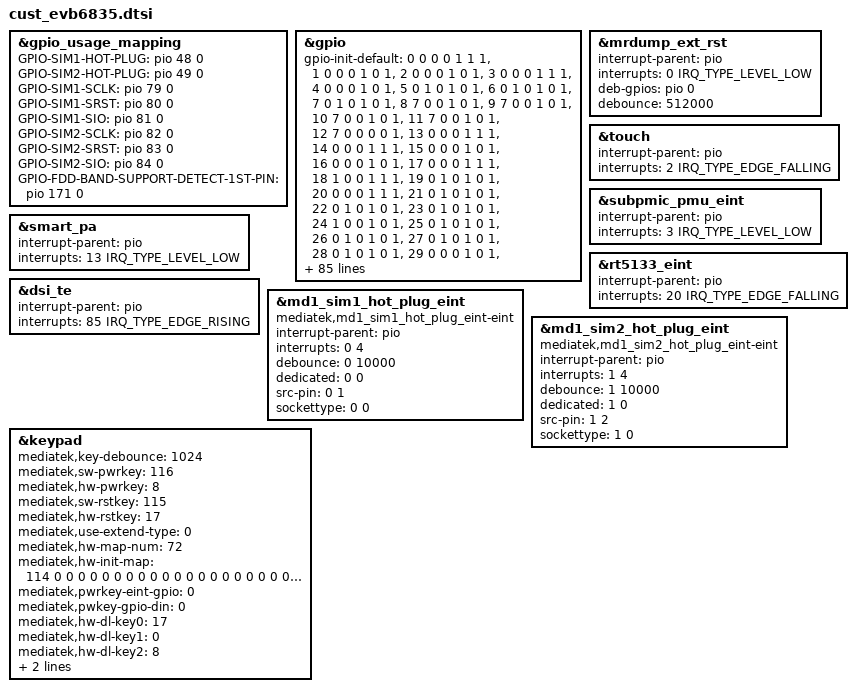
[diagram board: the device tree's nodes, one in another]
// SPDX-License-Identifier: (GPL-2.0-only OR BSD-2-Clause)
/*
 * Copyright (c) 2019 MediaTek Inc.
 */

/*
 * Generated by MTK SP DrvGen Version: 3.5.160809 for MT6835_6377.
 * 2022-09-23 20:14:52
 * Do Not Modify The File.
 * Copyright Mediatek Inc. (c) 2016.
 */

/*************************
 * ADC DTSI File
 ************************/



/*************************
 * CLK_BUF DTSI File
 ************************/



/*************************
 * I2C DTSI File
 ************************/



/*************************
 * GPIO DTSI File
 ************************/

&gpio_usage_mapping {
	GPIO-SIM1-HOT-PLUG = <&pio 48 0>;
	GPIO-SIM2-HOT-PLUG = <&pio 49 0>;
	GPIO-SIM1-SCLK = <&pio 79 0>;
	GPIO-SIM1-SRST = <&pio 80 0>;
	GPIO-SIM1-SIO = <&pio 81 0>;
	GPIO-SIM2-SCLK = <&pio 82 0>;
	GPIO-SIM2-SRST = <&pio 83 0>;
	GPIO-SIM2-SIO = <&pio 84 0>;
	GPIO-FDD-BAND-SUPPORT-DETECT-1ST-PIN = <&pio 171 0>;
};

&gpio{
	gpio-init-default = <0 0 0 0 1 1 1>,
		<1 0 0 0 1 0 1>,
		<2 0 0 0 1 0 1>,
		<3 0 0 0 1 1 1>,
		<4 0 0 0 1 0 1>,
		<5 0 1 0 1 0 1>,
		<6 0 1 0 1 0 1>,
		<7 0 1 0 1 0 1>,
		<8 7 0 0 1 0 1>,
		<9 7 0 0 1 0 1>,
		<10 7 0 0 1 0 1>,
		<11 7 0 0 1 0 1>,
		<12 7 0 0 0 0 1>,
		<13 0 0 0 1 1 1>,
		<14 0 0 0 1 1 1>,
		<15 0 0 0 1 0 1>,
		<16 0 0 0 1 0 1>,
		<17 0 0 0 1 1 1>,
		<18 1 0 0 1 1 1>,
		<19 0 1 0 1 0 1>,
		<20 0 0 0 1 1 1>,
		<21 0 1 0 1 0 1>,
		<22 0 1 0 1 0 1>,
		<23 0 1 0 1 0 1>,
		<24 1 0 0 1 0 1>,
		<25 0 1 0 1 0 1>,
		<26 0 1 0 1 0 1>,
		<27 0 1 0 1 0 1>,
		<28 0 1 0 1 0 1>,
		<29 0 0 0 1 0 1>,
		<30 0 1 0 1 0 1>,
		<31 1 0 0 1 1 1>,
		<32 7 0 0 1 1 1>,
		<33 7 0 0 1 0 1>,
		<34 3 0 0 1 0 1>,
		<35 3 0 0 1 1 1>,
		<36 1 0 0 1 0 1>,
		<37 1 0 0 1 0 1>,
		<38 1 0 0 1 0 1>,
		<39 1 0 0 1 0 1>,
		<40 1 0 0 1 0 1>,
		<41 1 0 0 1 0 1>,
		<42 1 0 0 1 0 1>,
		<43 0 1 0 1 0 1>,
		<44 1 0 0 0 0 1>,
		<45 1 0 0 1 0 1>,
		<46 1 0 0 0 0 1>,
		<47 3 0 0 1 0 1>,
		<48 1 0 0 1 1 1>,
		<49 1 0 0 1 1 1>,
		<50 1 0 0 0 0 1>,
		<51 1 0 0 1 1 1>,
		<52 1 0 0 0 0 1>,
		<53 1 0 0 1 1 1>,
		<54 0 1 0 1 0 1>,
		<55 7 0 0 1 0 1>,
		<56 7 0 0 1 0 1>,
		<57 7 0 0 1 0 1>,
		<58 7 0 0 0 0 1>,
		<59 7 0 0 1 0 1>,
		<60 2 0 0 1 0 1>,
		<61 2 0 0 1 1 1>,
		<62 2 0 0 1 0 1>,
		<63 2 0 0 1 0 1>,
		<64 1 0 0 1 0 1>,
		<65 1 0 0 1 1 1>,
		<66 1 0 0 1 0 1>,
		<67 1 0 0 1 0 1>,
		<68 1 0 0 1 0 1>,
		<69 1 0 0 1 1 1>,
		<70 1 0 0 1 0 1>,
		<71 1 0 0 1 0 1>,
		<73 1 0 0 0 0 1>,
		<74 1 0 0 1 1 1>,
		<75 1 0 0 1 1 1>,
		<76 1 0 0 1 1 1>,
		<77 1 0 0 1 1 1>,
		<78 1 0 0 1 1 1>,
		<79 1 0 0 0 0 1>,
		<80 1 0 0 0 0 1>,
		<81 1 0 0 1 1 1>,
		<82 1 0 0 0 0 1>,
		<83 1 0 0 0 0 1>,
		<84 1 0 0 1 1 1>,
		<85 1 0 0 1 0 1>,
		<86 1 0 0 0 0 1>,
		<87 1 0 0 0 0 1>,
		<88 1 0 0 1 0 1>,
		<89 1 0 0 1 0 1>,
		<90 1 0 0 1 0 1>,
		<91 1 0 0 1 0 1>,
		<92 0 0 0 1 0 1>,
		<93 1 0 0 1 0 1>,
		<94 1 0 0 1 0 1>,
		<95 1 0 0 0 0 1>,
		<96 1 0 0 0 0 1>,
		<97 1 0 0 0 0 1>,
		<98 1 0 0 0 0 1>,
		<99 1 0 0 0 0 1>,
		<100 1 0 0 0 0 1>,
		<101 1 0 0 0 0 1>,
		<102 1 0 0 0 0 1>,
		<103 1 0 0 0 0 1>,
		<104 1 0 0 0 0 1>,
		<105 1 0 0 0 0 1>,
		<106 1 0 0 0 0 1>,
		<107 1 0 0 0 0 1>,
		<108 1 0 0 0 0 1>,
		<109 1 0 0 0 0 1>,
		<110 1 0 0 0 0 1>,
		<111 1 0 0 0 0 1>,
		<112 1 0 0 0 0 1>,
		<113 1 0 0 0 0 1>,
		<114 1 0 0 0 0 1>,
		<115 1 0 0 0 0 0>,
		<116 1 0 0 1 0 0>,
		<117 1 0 0 0 0 0>,
		<118 1 0 0 1 0 0>,
		<119 1 0 0 0 0 0>,
		<120 1 0 0 1 0 0>,
		<121 1 0 0 0 0 0>,
		<122 1 0 0 1 0 0>,
		<123 4 0 0 1 0 1>,
		<124 4 0 0 1 0 1>,
		<125 1 0 0 1 0 1>,
		<126 1 0 0 1 0 1>,
		<127 0 0 0 1 0 1>,
		<128 0 0 0 1 0 1>,
		<129 2 0 0 1 1 1>,
		<130 2 0 0 1 1 1>,
		<131 1 0 0 1 1 1>,
		<132 1 0 0 1 1 1>,
		<133 0 1 1 1 0 1>,
		<134 0 1 0 1 0 1>,
		<135 1 0 0 1 1 1>,
		<136 1 0 0 1 1 1>,
		<137 1 0 0 1 1 1>,
		<138 1 0 0 1 1 1>,
		<139 1 0 0 1 1 1>,
		<140 1 0 0 1 1 1>,
		<141 0 1 0 1 0 1>,
		<142 0 1 0 1 0 1>,
		<143 1 0 0 1 1 1>,
		<144 1 0 0 1 1 1>,
		<145 3 0 0 1 1 1>,
		<146 3 0 0 1 1 1>,
		<147 0 1 0 1 0 1>,
		<148 0 1 0 1 0 1>,
		<149 4 0 0 1 0 1>,
		<150 0 1 0 1 0 1>,
		<151 0 0 0 1 0 1>,
		<152 1 0 0 0 0 1>,
		<153 1 0 0 0 0 1>,
		<154 1 0 0 0 0 1>,
		<155 1 0 0 0 0 1>,
		<156 1 0 0 0 0 1>,
		<157 1 0 0 0 0 1>,
		<158 1 0 0 0 0 1>,
		<159 1 0 0 1 0 1>,
		<160 1 0 0 0 0 1>,
		<161 1 0 0 0 0 1>,
		<162 1 0 0 0 0 1>,
		<163 1 0 0 0 0 1>,
		<164 1 0 0 0 0 1>,
		<165 0 0 0 1 0 1>,
		<166 1 0 0 0 0 1>,
		<167 1 0 0 0 0 1>,
		<168 1 0 0 1 0 1>,
		<169 1 0 0 1 0 1>,
		<170 0 1 0 1 0 1>,
		<171 0 0 0 0 0 1>,
		<172 0 0 0 1 0 1>,
		<173 0 0 0 1 0 1>,
		<174 0 0 0 1 0 1>,
		<175 0 0 0 1 0 1>,
		<176 0 0 0 1 0 1>,
		<177 0 0 0 1 0 1>,
		<178 0 0 0 1 0 1>,
		<179 0 0 0 1 0 1>,
		<180 0 0 0 1 0 1>,
		<193 0 0 0 1 0 0>,
		<194 0 0 0 1 0 0>,
		<195 0 0 0 1 0 0>,
		<196 0 0 0 1 0 0>,
		<197 0 0 0 1 0 0>,
		<198 0 0 0 1 0 0>,
		<199 0 0 0 1 0 0>,
		<200 0 0 0 1 0 0>,
		<201 0 0 0 1 0 0>,
		<202 0 0 0 1 0 0>,
		<203 0 0 0 1 0 0>,
		<204 0 0 0 1 0 0>,
		<205 0 0 0 1 0 0>,
		<206 0 0 0 1 0 0>,
		<207 0 0 0 1 0 0>,
		<208 0 0 0 1 0 0>,
		<209 0 0 0 1 0 0>,
		<210 0 0 0 1 0 0>,
		<211 0 0 0 1 0 0>,
		<212 0 0 0 1 0 0>;
};


/*************************
 * EINT DTSI File
 ************************/

#include <dt-bindings/interrupt-controller/irq.h>
#include <dt-bindings/interrupt-controller/arm-gic.h>

&mrdump_ext_rst {
	interrupt-parent = <&pio>;
	interrupts = <0 IRQ_TYPE_LEVEL_LOW>;
	deb-gpios = <&pio 0 0>;
	debounce = <512000>;
	status = "okay";
};

&touch {
	interrupt-parent = <&pio>;
	interrupts = <2 IRQ_TYPE_EDGE_FALLING>;
	status = "okay";
};

&subpmic_pmu_eint {
	interrupt-parent = <&pio>;
	interrupts = <3 IRQ_TYPE_LEVEL_LOW>;
	status = "okay";
};

&smart_pa {
	interrupt-parent = <&pio>;
	interrupts = <13 IRQ_TYPE_LEVEL_LOW>;
	status = "okay";
};

&rt5133_eint {
	interrupt-parent = <&pio>;
	interrupts = <20 IRQ_TYPE_EDGE_FALLING>;
	status = "okay";
};

&dsi_te {
	interrupt-parent = <&pio>;
	interrupts = <85 IRQ_TYPE_EDGE_RISING>;
	status = "okay";
};



/*************************
 * MD1_EINT DTSI File
 ************************/

&md1_sim1_hot_plug_eint {
	compatible = "mediatek,md1_sim1_hot_plug_eint-eint";
	interrupt-parent = <&pio>;
	interrupts = <0 4>;
	debounce = <0 10000>;
	dedicated = <0 0>;
	src-pin = <0 1>;
	sockettype = <0 0>;
	status = "okay";
};

&md1_sim2_hot_plug_eint {
	compatible = "mediatek,md1_sim2_hot_plug_eint-eint";
	interrupt-parent = <&pio>;
	interrupts = <1 4>;
	debounce = <1 10000>;
	dedicated = <1 0>;
	src-pin = <1 2>;
	sockettype = <1 0>;
	status = "okay";
};



/*************************
 * PMIC DTSI File
 ************************/



/*************************
 * POWER DTSI File
 ************************/



/*************************
 * KPD DTSI File
 ************************/

&keypad {
	mediatek,key-debounce = <1024>;
	mediatek,sw-pwrkey = <116>;
	mediatek,hw-pwrkey = <8>;
	mediatek,sw-rstkey  = <115>;
	mediatek,hw-rstkey = <17>;
	mediatek,use-extend-type = <0>;
	/*HW Keycode [0~71] -> Linux Keycode*/
	mediatek,hw-map-num = <72>;
	mediatek,hw-init-map = <114 0 0 0 0 0 0 0 0 0 0 0 0 0 0 0 0 0 0 0 0 0 0 0
				0 0 0 0 0 0 0 0 0 0 0 0 0 0 0 0 0 0 0 0 0 0 0 0
				0 0 0 0 0 0 0 0 0 0 0 0 0 0 0 0 0 0 0 0 0 0 0 0>;
	mediatek,pwrkey-eint-gpio = <0>;
	mediatek,pwkey-gpio-din  = <0>;
	mediatek,hw-dl-key0 = <17>;
	mediatek,hw-dl-key1 = <0>;
	mediatek,hw-dl-key2 = <8>;
	mediatek,hw-recovery-key = <17>;
	mediatek,hw-factory-key = <0>;
	status = "okay";
};


